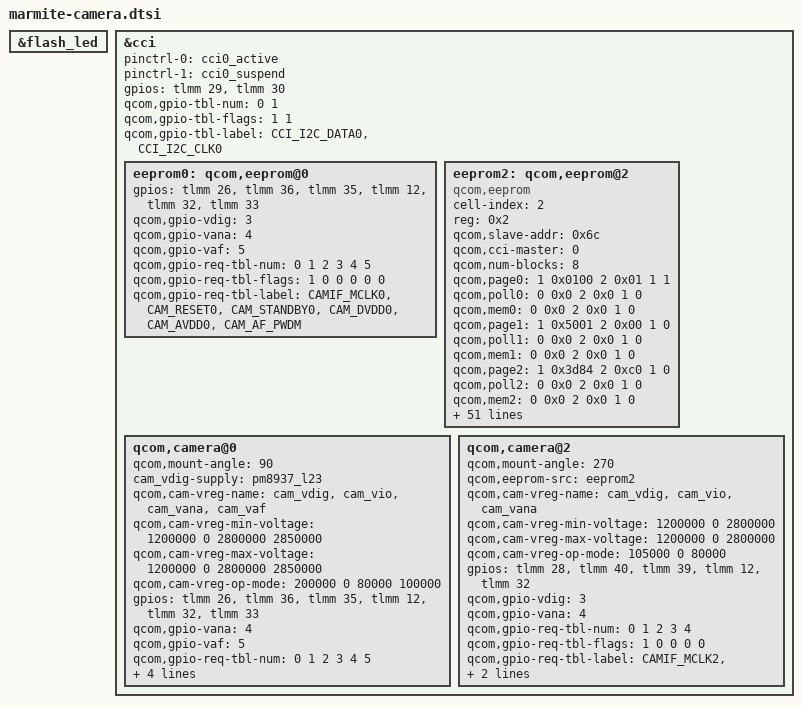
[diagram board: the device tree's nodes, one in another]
/* Copyright (c) 2020, The Linux Foundation. All rights reserved.
*  Copyright (c) 2020, Jebaitedneko.
*
* This program is free software; you can redistribute it and/or modify
* it under the terms of the GNU General Public License version 2 and
* only version 2 as published by the Free Software Foundation.
*
* This program is distributed in the hope that it will be useful,
* but WITHOUT ANY WARRANTY; without even the implied warranty of
* MERCHANTABILITY or FITNESS FOR A PARTICULAR PURPOSE.  See the
* GNU General Public License for more details.
*/

&flash_led {
	/delete-property/pinctrl-names;
	/delete-property/pinctrl-0;
	/delete-property/pinctrl-1;
	/delete-property/qcom,follow-otst2-rb-disabled;
};

&cci { 
	pinctrl-names = "cci_default", "cci_suspend";
	pinctrl-0 = <&cci0_active>;
	pinctrl-1 = <&cci0_suspend>;
	gpios = <&tlmm 29 0>,
	        <&tlmm 30 0>;
	qcom,gpio-tbl-num = <0 1>;
	qcom,gpio-tbl-flags = <1 1>;
	qcom,gpio-tbl-label = "CCI_I2C_DATA0",
				"CCI_I2C_CLK0";

	eeprom0: qcom,eeprom@0 {
                gpios = <&tlmm 26 0>,
                        <&tlmm 36 0>,
                        <&tlmm 35 0>,
                        <&tlmm 12 0>,
                        <&tlmm 32 0>,
                        <&tlmm 33 0>;
                qcom,gpio-vdig = <3>;
                qcom,gpio-vana = <4>;
                qcom,gpio-vaf = <5>;
                qcom,gpio-req-tbl-num = <0 1 2 3 4 5>;
                qcom,gpio-req-tbl-flags = <1 0 0 0 0 0>;
                qcom,gpio-req-tbl-label = "CAMIF_MCLK0",
                        "CAM_RESET0",
                        "CAM_STANDBY0",
                        "CAM_DVDD0",
                        "CAM_AVDD0",
                        "CAM_AF_PWDM";
	};

	/delete-node/qcom,eeprom@1;


	eeprom2: qcom,eeprom@2 {
		cell-index = <2>;
		reg = <0x2>;
		compatible = "qcom,eeprom";
                qcom,slave-addr = <0x6c>;
                qcom,cci-master = <0>;
                qcom,num-blocks = <8>;

                qcom,page0 = <1 0x0100 2 0x01 1 1>;
                qcom,poll0 = <0 0x0 2 0x0 1 0>;
                qcom,mem0 = <0 0x0 2 0x0 1 0>;

                qcom,page1 = <1 0x5001 2 0x00 1 0>;
                qcom,poll1 = <0 0x0 2 0x0 1 0>;
                qcom,mem1 = <0 0x0 2 0x0 1 0>;

                qcom,page2 = <1 0x3d84 2 0xc0 1 0>;
                qcom,poll2 = <0 0x0 2 0x0 1 0>;
                qcom,mem2 = <0 0x0 2 0x0 1 0>;

                qcom,page3 = <1 0x3d88 2 0x70 1 0>;
                qcom,poll3 = <0 0x0 2 0x0 1 0>;
                qcom,mem3 = <0 0x0 2 0x0 1 0>;

                qcom,page4 = <1 0x3d89 2 0x10 1 0>;
                qcom,poll4 = <0 0x0 2 0x0 1 0>;
                qcom,mem4 = <0 0x0 2 0x0 1 0>;

                qcom,page5 = <1 0x3d8a 2 0x70 1 0>;
                qcom,poll5 = <0 0x0 2 0x0 1 0>;
                qcom,mem5 = <0 0x0 2 0x0 1 0>;

                qcom,page6 = <1 0x3d8b 2 0xf4 1 0>;
                qcom,poll6 = <0 0x0 2 0x0 1 0>;
                qcom,mem6 = <0 0x0 2 0x0 1 0>;

                qcom,page7 = <1 0x3d81 2 0x01 1 10>;
                qcom,poll7 = <0 0x0 2 0x0 1 1>;
                qcom,mem7 = <1536 0x7010 2 0 1 0>;

		cam_vdig-supply = <&pm8937_l23>;
		cam_vana-supply = <&pm8937_l22>;
		cam_vio-supply = <&pm8937_l6>;
		qcom,cam-vreg-name = "cam_vdig", "cam_vio", "cam_vana";
		qcom,cam-vreg-min-voltage = <1200000 0 2800000>;
		qcom,cam-vreg-max-voltage = <1200000 0 2800000>;
		qcom,cam-vreg-op-mode = <105000 0 80000>;
                qcom,gpio-no-mux = <0>;
		pinctrl-names = "cam_default", "cam_suspend";
		pinctrl-0 = <&cam_sensor_mclk2_default
                	&cam_sensor_front1_default>;
		pinctrl-1 = <&cam_sensor_mclk2_sleep &cam_sensor_front1_sleep>;
		gpios = <&tlmm 28 0>,
                	<&tlmm 40 0>,
                	<&tlmm 39 0>,
                	<&tlmm 12 0>,
                	<&tlmm 32 0>;
		qcom,gpio-reset = <1>;
		qcom,gpio-standby = <2>;
                qcom,gpio-vdig = <3>;
                qcom,gpio-vana = <4>;
		qcom,gpio-req-tbl-num = <0 1 2 3 4>;
		qcom,gpio-req-tbl-flags = <1 0 0 0 0>;
		qcom,gpio-req-tbl-label = "CAMIF_MCLK2",
			"CAM_RESET2",
			"CAM_STANDBY2",
			"CAM_DVDD2",
			"CAM_AVDD2";
                qcom,cam-power-seq-type = "sensor_gpio", "sensor_gpio",
                        "sensor_vreg",
                        "sensor_gpio", "sensor_gpio" , "sensor_clk";
                qcom,cam-power-seq-val = "sensor_gpio_vdig", "sensor_gpio_vana", "cam_vio",
                        "sensor_gpio_reset", "sensor_gpio_standby",
                        "sensor_cam_mclk";
                qcom,cam-power-seq-cfg-val = <1 1 1 1 1 24000000>;
                qcom,cam-power-seq-delay = <1 1 1 30 30 5>;
		status = "ok";
		clocks = <&clock_gcc clk_mclk2_clk_src>,
				<&clock_gcc clk_gcc_camss_mclk2_clk>;
		clock-names = "cam_src_clk", "cam_clk";
		qcom,clock-rates = <19200000 0>;
	};

        qcom,camera@0 {
		qcom,mount-angle = <90>;
		cam_vdig-supply = <&pm8937_l23>;
		qcom,cam-vreg-name = "cam_vdig", "cam_vio", "cam_vana",
		                                        "cam_vaf";
		qcom,cam-vreg-min-voltage = <1200000 0 2800000 2850000>;
		qcom,cam-vreg-max-voltage = <1200000 0 2800000 2850000>;
		qcom,cam-vreg-op-mode = <200000 0 80000 100000>;
                gpios = <&tlmm 26 0>,
                        <&tlmm 36 0>,
                        <&tlmm 35 0>,
                        <&tlmm 12 0>,
                        <&tlmm 32 0>,
                        <&tlmm 33 0>;
                qcom,gpio-vana = <4>;
                qcom,gpio-vaf = <5>;
                qcom,gpio-req-tbl-num = <0 1 2 3 4 5>;
                qcom,gpio-req-tbl-flags = <1 0 0 0 0 0>;
                qcom,gpio-req-tbl-label = "CAMIF_MCLK0",
                        "CAM_RESET0",
                        "CAM_STANDBY0",
                        "CAM_DVDD0",
                        "CAM_AVDD0",
                        "CAM_AF_PWDM";
	};

        qcom,camera@2 {
                qcom,mount-angle = <270>;
                qcom,eeprom-src = <&eeprom2>;
		/delete-property/qcom,actuator-src;
		/delete-property/cam_vaf-supply;
		qcom,cam-vreg-name = "cam_vdig", "cam_vio", "cam_vana";
		qcom,cam-vreg-min-voltage = <1200000 0 2800000>;
		qcom,cam-vreg-max-voltage = <1200000 0 2800000>;
		qcom,cam-vreg-op-mode = <105000 0 80000>;

                gpios = <&tlmm 28 0>,
                        <&tlmm 40 0>,
                        <&tlmm 39 0>,
                        <&tlmm 12 0>,
                        <&tlmm 32 0>;
                qcom,gpio-vdig = <3>;
                qcom,gpio-vana = <4>;
                qcom,gpio-req-tbl-num = <0 1 2 3 4>;
                qcom,gpio-req-tbl-flags = <1 0 0 0 0>;
                qcom,gpio-req-tbl-label = "CAMIF_MCLK2",
                                          "CAM_RESET2",
                                          "CAM_STANDBY2",
                                          "CAM_DVDD2",
                                          "CAM_AVDD2";
	};
};

